VERSION "0.1.0"

NS_ :

BS_:

BU_: VehicleSim CruiseECU

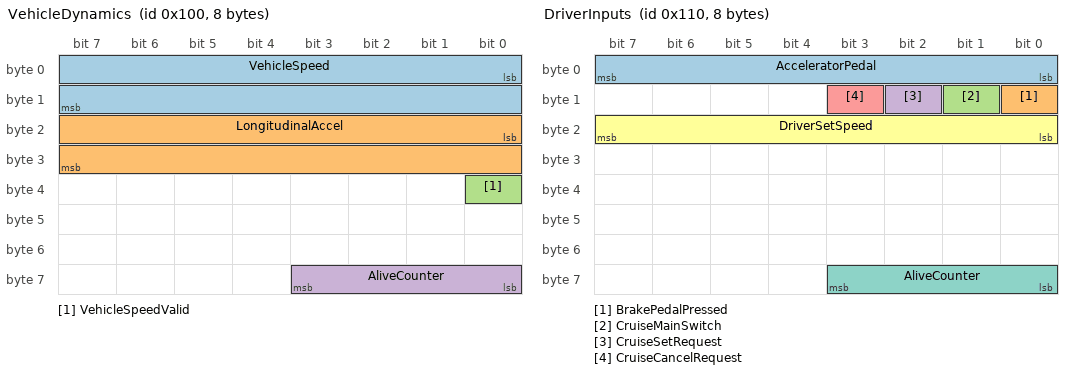
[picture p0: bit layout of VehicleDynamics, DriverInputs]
BO_ 256 VehicleDynamics: 8 VehicleSim
 SG_ VehicleSpeed : 0|16@1+ (0.01,0) [0|300] "km/h" CruiseECU
 SG_ LongitudinalAccel : 16|16@1- (0.001,0) [-20|20] "m/s2" CruiseECU
 SG_ VehicleSpeedValid : 32|1@1+ (1,0) [0|1] "" CruiseECU
 SG_ AliveCounter : 56|4@1+ (1,0) [0|15] "" CruiseECU

BO_ 272 DriverInputs: 8 VehicleSim
 SG_ AcceleratorPedal : 0|8@1+ (0.5,0) [0|100] "%" CruiseECU
 SG_ BrakePedalPressed : 8|1@1+ (1,0) [0|1] "" CruiseECU
 SG_ CruiseMainSwitch : 9|1@1+ (1,0) [0|1] "" CruiseECU
 SG_ CruiseSetRequest : 10|1@1+ (1,0) [0|1] "" CruiseECU
 SG_ CruiseCancelRequest : 11|1@1+ (1,0) [0|1] "" CruiseECU
 SG_ DriverSetSpeed : 16|8@1+ (1,0) [0|200] "km/h" CruiseECU
 SG_ AliveCounter : 56|4@1+ (1,0) [0|15] "" CruiseECU

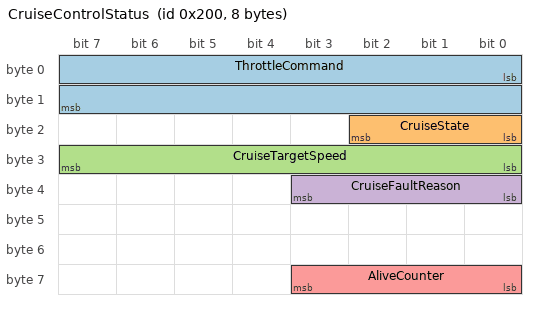
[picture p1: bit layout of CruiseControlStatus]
BO_ 512 CruiseControlStatus: 8 CruiseECU
 SG_ ThrottleCommand : 0|16@1+ (0.01,0) [0|100] "%" VehicleSim
 SG_ CruiseState : 16|3@1+ (1,0) [0|4] "" VehicleSim
 SG_ CruiseTargetSpeed : 24|8@1+ (1,0) [0|200] "km/h" VehicleSim
 SG_ CruiseFaultReason : 32|4@1+ (1,0) [0|15] "" VehicleSim
 SG_ AliveCounter : 56|4@1+ (1,0) [0|15] "" VehicleSim

CM_ "Virtual Automotive ECU Platform - educational CAN matrix (Classic CAN, 11-bit IDs). UDS diagnostics over ISO-TP use 0x7E0 (physical request), 0x7DF (functional request) and 0x7E8 (response); they are transport frames and not described as signals here.";
CM_ BO_ 256 "Vehicle motion state published by the vehicle simulator.";
CM_ BO_ 272 "Driver pedal and cruise-control switch inputs.";
CM_ BO_ 512 "Cruise control ECU output and state.";
CM_ SG_ 256 AliveCounter "4-bit rolling counter, increments by 1 per transmission (mod 16).";
CM_ SG_ 272 AliveCounter "4-bit rolling counter, increments by 1 per transmission (mod 16).";
CM_ SG_ 512 AliveCounter "4-bit rolling counter, increments by 1 per transmission (mod 16).";
BA_DEF_ BO_ "GenMsgCycleTime" INT 0 10000;
BA_DEF_ BO_ "VECU_RxTimeoutMs" INT 0 10000;
BA_DEF_DEF_ "GenMsgCycleTime" 0;
BA_DEF_DEF_ "VECU_RxTimeoutMs" 0;
BA_ "GenMsgCycleTime" BO_ 256 20;
BA_ "VECU_RxTimeoutMs" BO_ 256 100;
BA_ "GenMsgCycleTime" BO_ 272 50;
BA_ "VECU_RxTimeoutMs" BO_ 272 250;
BA_ "GenMsgCycleTime" BO_ 512 20;
BA_ "VECU_RxTimeoutMs" BO_ 512 100;
VAL_ 512 CruiseState 0 "Off" 1 "Standby" 2 "Active" 3 "Override" 4 "Fault" ;
VAL_ 512 CruiseFaultReason 0 "None" 1 "SpeedSignalTimeout" 2 "DriverInputTimeout" 3 "SpeedInvalid" 4 "InputsStale" 5 "ControllerFault" 6 "FunctionInhibited" 7 "WatchdogSafeState" 8 "ControlOutputStale" ;
